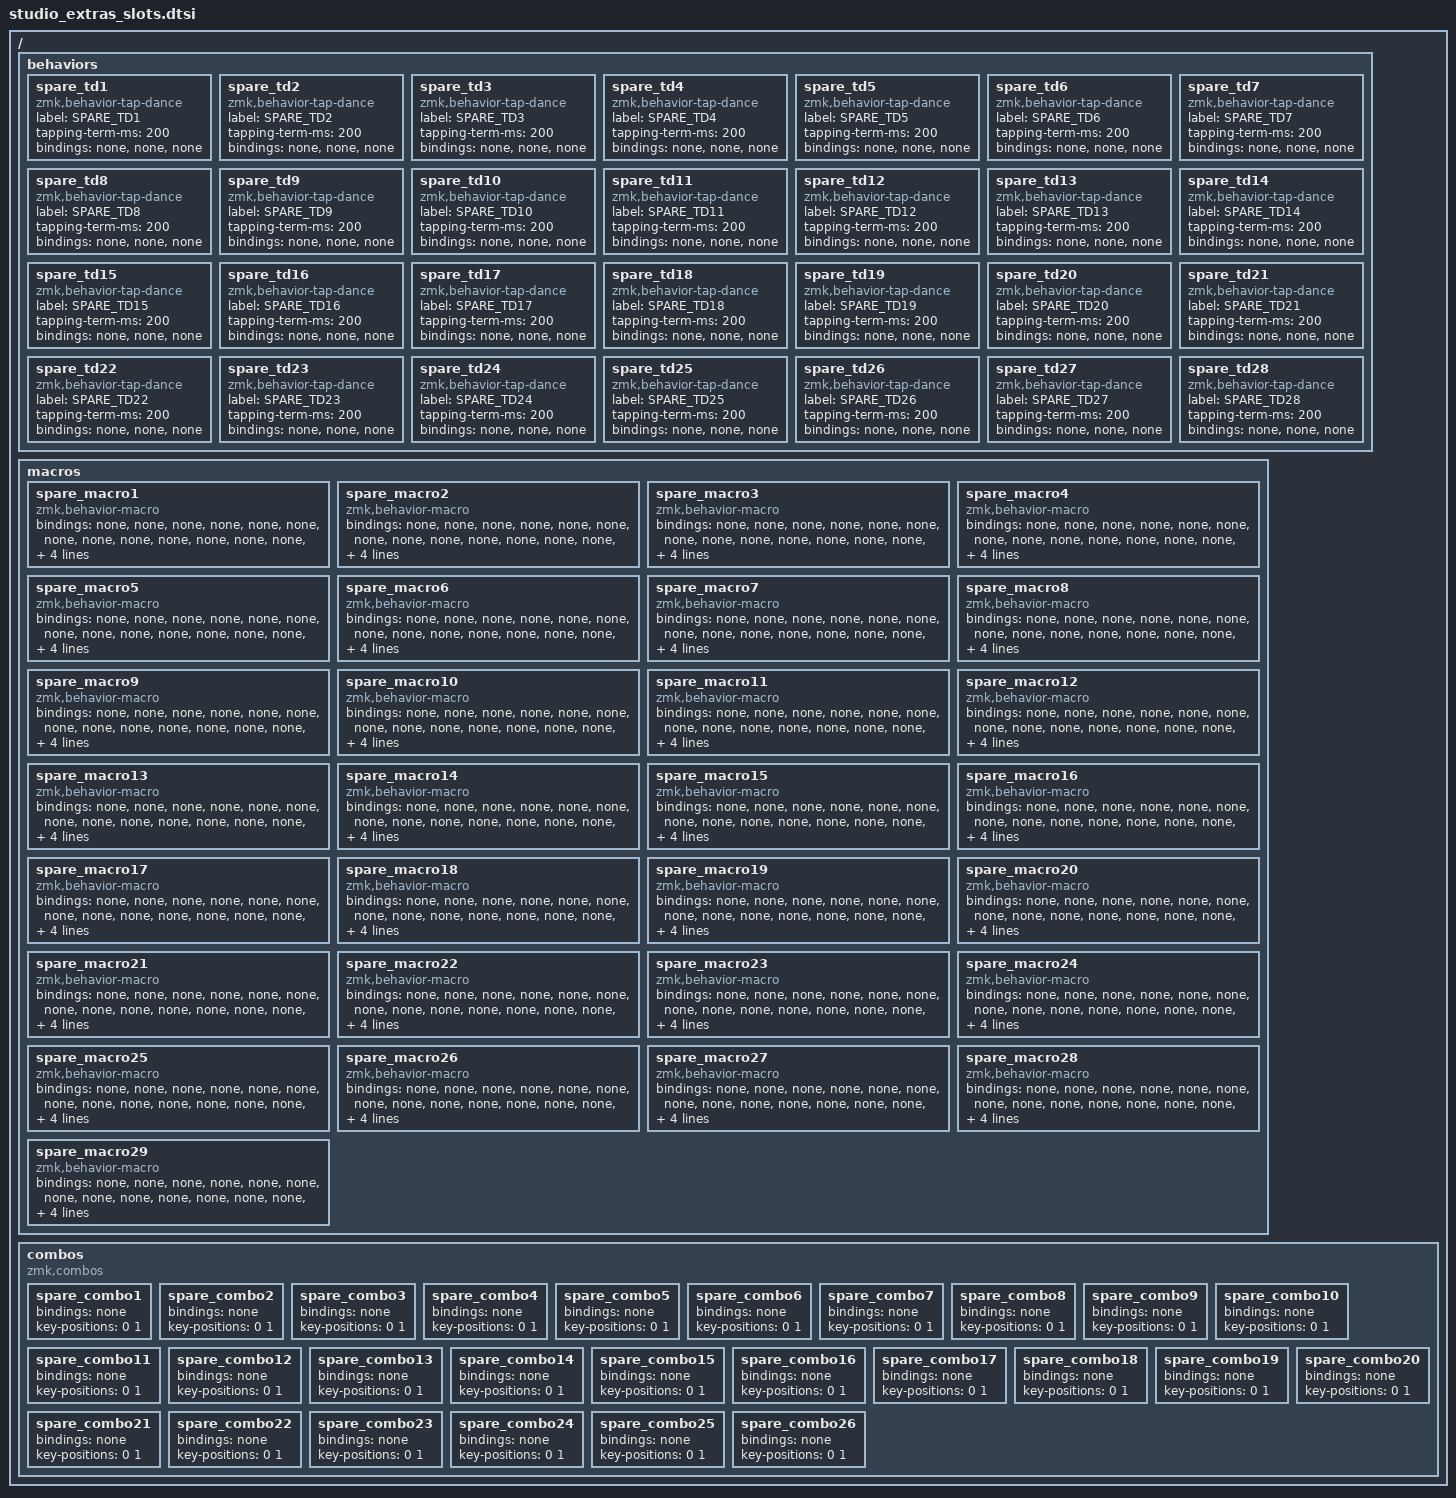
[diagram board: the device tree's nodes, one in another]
/*
 * studio-extras: spare slots for the chibiboard app
 * Edit combos / tap-dances / macros from the app. Empty slots (&none) never fire.
 *
 * Add one line near the top of your .keymap:
 *     #include "studio_extras_slots.dtsi"
 */

/ {
    behaviors {
        spare_td1: spare_td1 { compatible = "zmk,behavior-tap-dance"; label = "SPARE_TD1"; #binding-cells = <0>; tapping-term-ms = <200>; bindings = <&none>, <&none>, <&none>; };
        spare_td2: spare_td2 { compatible = "zmk,behavior-tap-dance"; label = "SPARE_TD2"; #binding-cells = <0>; tapping-term-ms = <200>; bindings = <&none>, <&none>, <&none>; };
        spare_td3: spare_td3 { compatible = "zmk,behavior-tap-dance"; label = "SPARE_TD3"; #binding-cells = <0>; tapping-term-ms = <200>; bindings = <&none>, <&none>, <&none>; };
        spare_td4: spare_td4 { compatible = "zmk,behavior-tap-dance"; label = "SPARE_TD4"; #binding-cells = <0>; tapping-term-ms = <200>; bindings = <&none>, <&none>, <&none>; };
        spare_td5: spare_td5 { compatible = "zmk,behavior-tap-dance"; label = "SPARE_TD5"; #binding-cells = <0>; tapping-term-ms = <200>; bindings = <&none>, <&none>, <&none>; };
        spare_td6: spare_td6 { compatible = "zmk,behavior-tap-dance"; label = "SPARE_TD6"; #binding-cells = <0>; tapping-term-ms = <200>; bindings = <&none>, <&none>, <&none>; };
        spare_td7: spare_td7 { compatible = "zmk,behavior-tap-dance"; label = "SPARE_TD7"; #binding-cells = <0>; tapping-term-ms = <200>; bindings = <&none>, <&none>, <&none>; };
        spare_td8: spare_td8 { compatible = "zmk,behavior-tap-dance"; label = "SPARE_TD8"; #binding-cells = <0>; tapping-term-ms = <200>; bindings = <&none>, <&none>, <&none>; };
        spare_td9: spare_td9 { compatible = "zmk,behavior-tap-dance"; label = "SPARE_TD9"; #binding-cells = <0>; tapping-term-ms = <200>; bindings = <&none>, <&none>, <&none>; };
        spare_td10: spare_td10 { compatible = "zmk,behavior-tap-dance"; label = "SPARE_TD10"; #binding-cells = <0>; tapping-term-ms = <200>; bindings = <&none>, <&none>, <&none>; };
        spare_td11: spare_td11 { compatible = "zmk,behavior-tap-dance"; label = "SPARE_TD11"; #binding-cells = <0>; tapping-term-ms = <200>; bindings = <&none>, <&none>, <&none>; };
        spare_td12: spare_td12 { compatible = "zmk,behavior-tap-dance"; label = "SPARE_TD12"; #binding-cells = <0>; tapping-term-ms = <200>; bindings = <&none>, <&none>, <&none>; };
        spare_td13: spare_td13 { compatible = "zmk,behavior-tap-dance"; label = "SPARE_TD13"; #binding-cells = <0>; tapping-term-ms = <200>; bindings = <&none>, <&none>, <&none>; };
        spare_td14: spare_td14 { compatible = "zmk,behavior-tap-dance"; label = "SPARE_TD14"; #binding-cells = <0>; tapping-term-ms = <200>; bindings = <&none>, <&none>, <&none>; };
        spare_td15: spare_td15 { compatible = "zmk,behavior-tap-dance"; label = "SPARE_TD15"; #binding-cells = <0>; tapping-term-ms = <200>; bindings = <&none>, <&none>, <&none>; };
        spare_td16: spare_td16 { compatible = "zmk,behavior-tap-dance"; label = "SPARE_TD16"; #binding-cells = <0>; tapping-term-ms = <200>; bindings = <&none>, <&none>, <&none>; };
        spare_td17: spare_td17 { compatible = "zmk,behavior-tap-dance"; label = "SPARE_TD17"; #binding-cells = <0>; tapping-term-ms = <200>; bindings = <&none>, <&none>, <&none>; };
        spare_td18: spare_td18 { compatible = "zmk,behavior-tap-dance"; label = "SPARE_TD18"; #binding-cells = <0>; tapping-term-ms = <200>; bindings = <&none>, <&none>, <&none>; };
        spare_td19: spare_td19 { compatible = "zmk,behavior-tap-dance"; label = "SPARE_TD19"; #binding-cells = <0>; tapping-term-ms = <200>; bindings = <&none>, <&none>, <&none>; };
        spare_td20: spare_td20 { compatible = "zmk,behavior-tap-dance"; label = "SPARE_TD20"; #binding-cells = <0>; tapping-term-ms = <200>; bindings = <&none>, <&none>, <&none>; };
        spare_td21: spare_td21 { compatible = "zmk,behavior-tap-dance"; label = "SPARE_TD21"; #binding-cells = <0>; tapping-term-ms = <200>; bindings = <&none>, <&none>, <&none>; };
        spare_td22: spare_td22 { compatible = "zmk,behavior-tap-dance"; label = "SPARE_TD22"; #binding-cells = <0>; tapping-term-ms = <200>; bindings = <&none>, <&none>, <&none>; };
        spare_td23: spare_td23 { compatible = "zmk,behavior-tap-dance"; label = "SPARE_TD23"; #binding-cells = <0>; tapping-term-ms = <200>; bindings = <&none>, <&none>, <&none>; };
        spare_td24: spare_td24 { compatible = "zmk,behavior-tap-dance"; label = "SPARE_TD24"; #binding-cells = <0>; tapping-term-ms = <200>; bindings = <&none>, <&none>, <&none>; };
        spare_td25: spare_td25 { compatible = "zmk,behavior-tap-dance"; label = "SPARE_TD25"; #binding-cells = <0>; tapping-term-ms = <200>; bindings = <&none>, <&none>, <&none>; };
        spare_td26: spare_td26 { compatible = "zmk,behavior-tap-dance"; label = "SPARE_TD26"; #binding-cells = <0>; tapping-term-ms = <200>; bindings = <&none>, <&none>, <&none>; };
        spare_td27: spare_td27 { compatible = "zmk,behavior-tap-dance"; label = "SPARE_TD27"; #binding-cells = <0>; tapping-term-ms = <200>; bindings = <&none>, <&none>, <&none>; };
        spare_td28: spare_td28 { compatible = "zmk,behavior-tap-dance"; label = "SPARE_TD28"; #binding-cells = <0>; tapping-term-ms = <200>; bindings = <&none>, <&none>, <&none>; };
    };

    macros {
        spare_macro1: spare_macro1 { compatible = "zmk,behavior-macro"; #binding-cells = <0>; bindings = <&none &none &none &none &none &none &none &none &none &none &none &none &none &none &none &none &none &none &none &none &none &none &none &none &none &none &none &none &none &none>; label = "SPARE_MACRO1"; };
        spare_macro2: spare_macro2 { compatible = "zmk,behavior-macro"; #binding-cells = <0>; bindings = <&none &none &none &none &none &none &none &none &none &none &none &none &none &none &none &none &none &none &none &none &none &none &none &none &none &none &none &none &none &none>; label = "SPARE_MACRO2"; };
        spare_macro3: spare_macro3 { compatible = "zmk,behavior-macro"; #binding-cells = <0>; bindings = <&none &none &none &none &none &none &none &none &none &none &none &none &none &none &none &none &none &none &none &none &none &none &none &none &none &none &none &none &none &none>; label = "SPARE_MACRO3"; };
        spare_macro4: spare_macro4 { compatible = "zmk,behavior-macro"; #binding-cells = <0>; bindings = <&none &none &none &none &none &none &none &none &none &none &none &none &none &none &none &none &none &none &none &none &none &none &none &none &none &none &none &none &none &none>; label = "SPARE_MACRO4"; };
        spare_macro5: spare_macro5 { compatible = "zmk,behavior-macro"; #binding-cells = <0>; bindings = <&none &none &none &none &none &none &none &none &none &none &none &none &none &none &none &none &none &none &none &none &none &none &none &none &none &none &none &none &none &none>; label = "SPARE_MACRO5"; };
        spare_macro6: spare_macro6 { compatible = "zmk,behavior-macro"; #binding-cells = <0>; bindings = <&none &none &none &none &none &none &none &none &none &none &none &none &none &none &none &none &none &none &none &none &none &none &none &none &none &none &none &none &none &none>; label = "SPARE_MACRO6"; };
        spare_macro7: spare_macro7 { compatible = "zmk,behavior-macro"; #binding-cells = <0>; bindings = <&none &none &none &none &none &none &none &none &none &none &none &none &none &none &none &none &none &none &none &none &none &none &none &none &none &none &none &none &none &none>; label = "SPARE_MACRO7"; };
        spare_macro8: spare_macro8 { compatible = "zmk,behavior-macro"; #binding-cells = <0>; bindings = <&none &none &none &none &none &none &none &none &none &none &none &none &none &none &none &none &none &none &none &none &none &none &none &none &none &none &none &none &none &none>; label = "SPARE_MACRO8"; };
        spare_macro9: spare_macro9 { compatible = "zmk,behavior-macro"; #binding-cells = <0>; bindings = <&none &none &none &none &none &none &none &none &none &none &none &none &none &none &none &none &none &none &none &none &none &none &none &none &none &none &none &none &none &none>; label = "SPARE_MACRO9"; };
        spare_macro10: spare_macro10 { compatible = "zmk,behavior-macro"; #binding-cells = <0>; bindings = <&none &none &none &none &none &none &none &none &none &none &none &none &none &none &none &none &none &none &none &none &none &none &none &none &none &none &none &none &none &none>; label = "SPARE_MACRO10"; };
        spare_macro11: spare_macro11 { compatible = "zmk,behavior-macro"; #binding-cells = <0>; bindings = <&none &none &none &none &none &none &none &none &none &none &none &none &none &none &none &none &none &none &none &none &none &none &none &none &none &none &none &none &none &none>; label = "SPARE_MACRO11"; };
        spare_macro12: spare_macro12 { compatible = "zmk,behavior-macro"; #binding-cells = <0>; bindings = <&none &none &none &none &none &none &none &none &none &none &none &none &none &none &none &none &none &none &none &none &none &none &none &none &none &none &none &none &none &none>; label = "SPARE_MACRO12"; };
        spare_macro13: spare_macro13 { compatible = "zmk,behavior-macro"; #binding-cells = <0>; bindings = <&none &none &none &none &none &none &none &none &none &none &none &none &none &none &none &none &none &none &none &none &none &none &none &none &none &none &none &none &none &none>; label = "SPARE_MACRO13"; };
        spare_macro14: spare_macro14 { compatible = "zmk,behavior-macro"; #binding-cells = <0>; bindings = <&none &none &none &none &none &none &none &none &none &none &none &none &none &none &none &none &none &none &none &none &none &none &none &none &none &none &none &none &none &none>; label = "SPARE_MACRO14"; };
        spare_macro15: spare_macro15 { compatible = "zmk,behavior-macro"; #binding-cells = <0>; bindings = <&none &none &none &none &none &none &none &none &none &none &none &none &none &none &none &none &none &none &none &none &none &none &none &none &none &none &none &none &none &none>; label = "SPARE_MACRO15"; };
        spare_macro16: spare_macro16 { compatible = "zmk,behavior-macro"; #binding-cells = <0>; bindings = <&none &none &none &none &none &none &none &none &none &none &none &none &none &none &none &none &none &none &none &none &none &none &none &none &none &none &none &none &none &none>; label = "SPARE_MACRO16"; };
        spare_macro17: spare_macro17 { compatible = "zmk,behavior-macro"; #binding-cells = <0>; bindings = <&none &none &none &none &none &none &none &none &none &none &none &none &none &none &none &none &none &none &none &none &none &none &none &none &none &none &none &none &none &none>; label = "SPARE_MACRO17"; };
        spare_macro18: spare_macro18 { compatible = "zmk,behavior-macro"; #binding-cells = <0>; bindings = <&none &none &none &none &none &none &none &none &none &none &none &none &none &none &none &none &none &none &none &none &none &none &none &none &none &none &none &none &none &none>; label = "SPARE_MACRO18"; };
        spare_macro19: spare_macro19 { compatible = "zmk,behavior-macro"; #binding-cells = <0>; bindings = <&none &none &none &none &none &none &none &none &none &none &none &none &none &none &none &none &none &none &none &none &none &none &none &none &none &none &none &none &none &none>; label = "SPARE_MACRO19"; };
        spare_macro20: spare_macro20 { compatible = "zmk,behavior-macro"; #binding-cells = <0>; bindings = <&none &none &none &none &none &none &none &none &none &none &none &none &none &none &none &none &none &none &none &none &none &none &none &none &none &none &none &none &none &none>; label = "SPARE_MACRO20"; };
        spare_macro21: spare_macro21 { compatible = "zmk,behavior-macro"; #binding-cells = <0>; bindings = <&none &none &none &none &none &none &none &none &none &none &none &none &none &none &none &none &none &none &none &none &none &none &none &none &none &none &none &none &none &none>; label = "SPARE_MACRO21"; };
        spare_macro22: spare_macro22 { compatible = "zmk,behavior-macro"; #binding-cells = <0>; bindings = <&none &none &none &none &none &none &none &none &none &none &none &none &none &none &none &none &none &none &none &none &none &none &none &none &none &none &none &none &none &none>; label = "SPARE_MACRO22"; };
        spare_macro23: spare_macro23 { compatible = "zmk,behavior-macro"; #binding-cells = <0>; bindings = <&none &none &none &none &none &none &none &none &none &none &none &none &none &none &none &none &none &none &none &none &none &none &none &none &none &none &none &none &none &none>; label = "SPARE_MACRO23"; };
        spare_macro24: spare_macro24 { compatible = "zmk,behavior-macro"; #binding-cells = <0>; bindings = <&none &none &none &none &none &none &none &none &none &none &none &none &none &none &none &none &none &none &none &none &none &none &none &none &none &none &none &none &none &none>; label = "SPARE_MACRO24"; };
        spare_macro25: spare_macro25 { compatible = "zmk,behavior-macro"; #binding-cells = <0>; bindings = <&none &none &none &none &none &none &none &none &none &none &none &none &none &none &none &none &none &none &none &none &none &none &none &none &none &none &none &none &none &none>; label = "SPARE_MACRO25"; };
        spare_macro26: spare_macro26 { compatible = "zmk,behavior-macro"; #binding-cells = <0>; bindings = <&none &none &none &none &none &none &none &none &none &none &none &none &none &none &none &none &none &none &none &none &none &none &none &none &none &none &none &none &none &none>; label = "SPARE_MACRO26"; };
        spare_macro27: spare_macro27 { compatible = "zmk,behavior-macro"; #binding-cells = <0>; bindings = <&none &none &none &none &none &none &none &none &none &none &none &none &none &none &none &none &none &none &none &none &none &none &none &none &none &none &none &none &none &none>; label = "SPARE_MACRO27"; };
        spare_macro28: spare_macro28 { compatible = "zmk,behavior-macro"; #binding-cells = <0>; bindings = <&none &none &none &none &none &none &none &none &none &none &none &none &none &none &none &none &none &none &none &none &none &none &none &none &none &none &none &none &none &none>; label = "SPARE_MACRO28"; };
        spare_macro29: spare_macro29 { compatible = "zmk,behavior-macro"; #binding-cells = <0>; bindings = <&none &none &none &none &none &none &none &none &none &none &none &none &none &none &none &none &none &none &none &none &none &none &none &none &none &none &none &none &none &none>; label = "SPARE_MACRO29"; };
    };

    combos {
        compatible = "zmk,combos";
        spare_combo1 { bindings = <&none>; key-positions = <0 1>; };
        spare_combo2 { bindings = <&none>; key-positions = <0 1>; };
        spare_combo3 { bindings = <&none>; key-positions = <0 1>; };
        spare_combo4 { bindings = <&none>; key-positions = <0 1>; };
        spare_combo5 { bindings = <&none>; key-positions = <0 1>; };
        spare_combo6 { bindings = <&none>; key-positions = <0 1>; };
        spare_combo7 { bindings = <&none>; key-positions = <0 1>; };
        spare_combo8 { bindings = <&none>; key-positions = <0 1>; };
        spare_combo9 { bindings = <&none>; key-positions = <0 1>; };
        spare_combo10 { bindings = <&none>; key-positions = <0 1>; };
        spare_combo11 { bindings = <&none>; key-positions = <0 1>; };
        spare_combo12 { bindings = <&none>; key-positions = <0 1>; };
        spare_combo13 { bindings = <&none>; key-positions = <0 1>; };
        spare_combo14 { bindings = <&none>; key-positions = <0 1>; };
        spare_combo15 { bindings = <&none>; key-positions = <0 1>; };
        spare_combo16 { bindings = <&none>; key-positions = <0 1>; };
        spare_combo17 { bindings = <&none>; key-positions = <0 1>; };
        spare_combo18 { bindings = <&none>; key-positions = <0 1>; };
        spare_combo19 { bindings = <&none>; key-positions = <0 1>; };
        spare_combo20 { bindings = <&none>; key-positions = <0 1>; };
        spare_combo21 { bindings = <&none>; key-positions = <0 1>; };
        spare_combo22 { bindings = <&none>; key-positions = <0 1>; };
        spare_combo23 { bindings = <&none>; key-positions = <0 1>; };
        spare_combo24 { bindings = <&none>; key-positions = <0 1>; };
        spare_combo25 { bindings = <&none>; key-positions = <0 1>; };
        spare_combo26 { bindings = <&none>; key-positions = <0 1>; };
    };
};
